# STM32L452xx register map
File version: 1.0
Registers are 32-bit, read-write, reset 0x0 unless marked. A register's access mark holds for its fields unless they carry their own. Offsets are from the block's base; [hi:lo] are bit positions; lines under a group give offsets from that group; {n}, {i} and the like mark numbered series.

## CRC — CRC calculation unit
Base 0x40023000
0x00 DR — CRC Data register
  [31:0] DR — Data register bits
0x04 IDR 8-bit — CRC Independent data register
  [7:0] IDR — General-purpose 8-bit data register bits
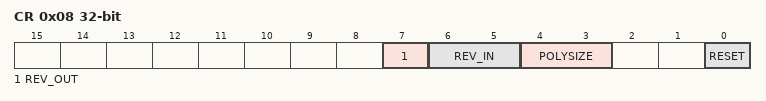
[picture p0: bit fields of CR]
0x08 CR — CRC Control register
  [7] REV_OUT — REV_OUT Reverse Output Data bits
    0=NONE (Output Data bit order not affected); 1=BIT (Output Data bit reversal done by bit)
  [6:5] REV_IN — REV_IN Reverse Input Data bits
    0=NONE (Input Data bit order not affected); 1=BYTE (Input Data bit reversal done by byte); 2=HALFWORD (Input Data bit reversal done by half-word); 3=WORD (Input Data bit reversal done by word)
  [4:3] POLYSIZE — Polynomial size bits
    0=POLYLENGTH_32B (32 bits Polynomial size); 1=POLYLENGTH_16B (16 bits Polynomial size); 2=POLYLENGTH_8B (8 bits Polynomial size); 3=POLYLENGTH_7B (7 bits Polynomial size)
  [0] RESET — RESET the CRC computation unit bit
0x10 INIT — Initial CRC value register
  [31:0] INIT — Initial CRC value bits
0x14 POL — CRC polynomial register
  [31:0] POL — Coefficients of the polynomial

## TSC — Touch Sensing Controller (TSC)
Base 0x40024000
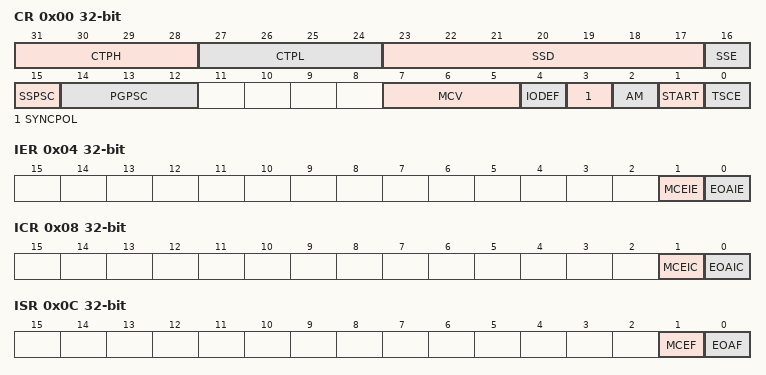
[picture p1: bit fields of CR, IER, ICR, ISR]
0x00 CR — TSC control register
  [31:28] CTPH — CTPH[3:0] bits (Charge Transfer pulse high)
  [27:24] CTPL — CTPL[3:0] bits (Charge Transfer pulse low)
  [23:17] SSD — SSD[6:0] bits (Spread Spectrum Deviation)
  [16] SSE — Spread Spectrum Enable
  [15] SSPSC — Spread Spectrum Prescaler
  [14:12] PGPSC — PGPSC[2:0] bits (Pulse Generator Prescaler)
  [7:5] MCV — MCV[2:0] bits (Max Count Value)
  [4] IODEF — IO default mode
  [3] SYNCPOL — Synchronization pin polarity
  [2] AM — Acquisition mode
  [1] START — Start acquisition
  [0] TSCE — Touch sensing controller enable
0x04 IER — TSC interrupt enable register
  [1] MCEIE — Max count error interrupt enable
  [0] EOAIE — End of acquisition interrupt enable
0x08 ICR — TSC interrupt clear register
  [1] MCEIC — Max count error interrupt clear
  [0] EOAIC — End of acquisition interrupt clear
0x0C ISR — TSC interrupt status register
  [1] MCEF — Max count error flag
  [0] EOAF — End of acquisition flag
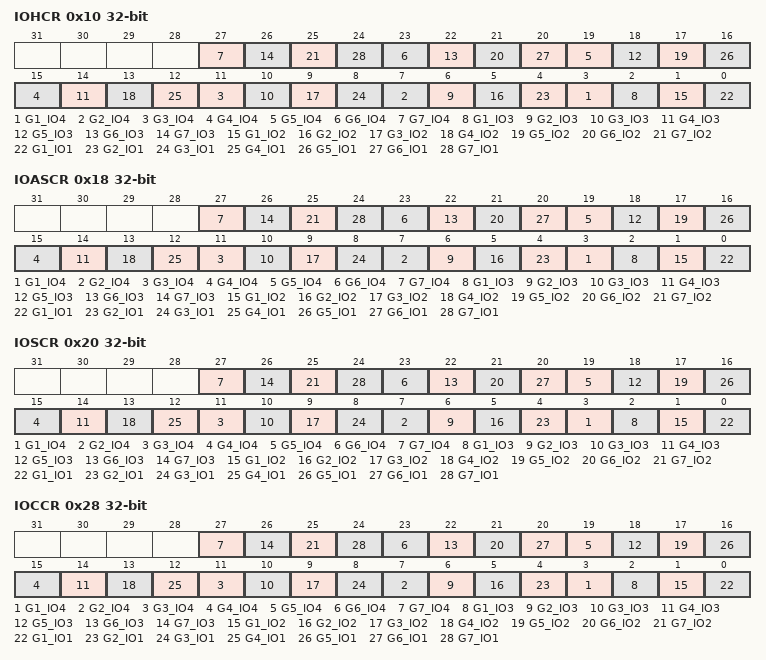
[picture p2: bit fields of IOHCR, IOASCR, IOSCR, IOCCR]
0x10 IOHCR — TSC I/O hysteresis control register
  [4n-1] G{n}_IO4 (n=1..7) — GROUP{n}_IO4 schmitt trigger hysteresis mode
  [4n-2] G{n}_IO3 (n=1..7) — GROUP{n}_IO3 schmitt trigger hysteresis mode
  [4n-3] G{n}_IO2 (n=1..7) — GROUP{n}_IO2 schmitt trigger hysteresis mode
  [4n-4] G{n}_IO1 (n=1..7) — GROUP{n}_IO1 schmitt trigger hysteresis mode
0x18 IOASCR — TSC I/O analog switch control register
  [4n-1] G{n}_IO4 (n=1..7) — GROUP{n}_IO4 analog switch enable
  [4n-2] G{n}_IO3 (n=1..7) — GROUP{n}_IO3 analog switch enable
  [4n-3] G{n}_IO2 (n=1..7) — GROUP{n}_IO2 analog switch enable
  [4n-4] G{n}_IO1 (n=1..7) — GROUP{n}_IO1 analog switch enable
0x20 IOSCR — TSC I/O sampling control register
  [4n-1] G{n}_IO4 (n=1..7) — GROUP{n}_IO4 sampling mode
  [4n-2] G{n}_IO3 (n=1..7) — GROUP{n}_IO3 sampling mode
  [4n-3] G{n}_IO2 (n=1..7) — GROUP{n}_IO2 sampling mode
  [4n-4] G{n}_IO1 (n=1..7) — GROUP{n}_IO1 sampling mode
0x28 IOCCR — TSC I/O channel control register
  [4n-1] G{n}_IO4 (n=1..7) — GROUP{n}_IO4 channel mode
  [4n-2] G{n}_IO3 (n=1..7) — GROUP{n}_IO3 channel mode
  [4n-3] G{n}_IO2 (n=1..7) — GROUP{n}_IO2 channel mode
  [4n-4] G{n}_IO1 (n=1..7) — GROUP{n}_IO1 channel mode
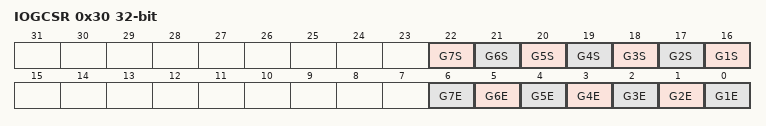
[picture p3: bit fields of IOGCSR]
0x30 IOGCSR — TSC I/O group control status register
  [n+15] G{n}S (n=1..7) — Analog IO GROUP{n} status
  [n-1] G{n}E (n=1..7) — Analog IO GROUP{n} enable
{0x30+4i} IOG{i}CR (i=1..7) — TSC I/O group x counter register
  [13:0] CNT — CNT[13:0] bits (Counter value)

## GPIOA — General Purpose I/O
Base 0x48000000
Same registers: GPIOB 0x48000400, GPIOC 0x48000800, GPIOD 0x48000C00, GPIOE 0x48001000, GPIOH 0x48001C00
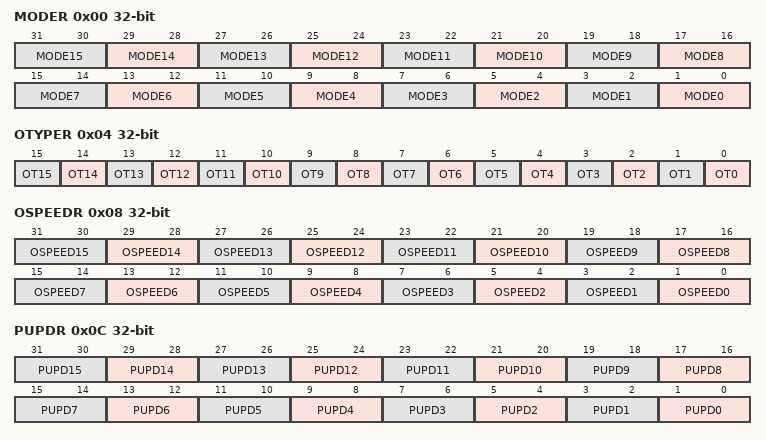
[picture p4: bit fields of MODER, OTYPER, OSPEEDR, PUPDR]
0x00 MODER — GPIO port mode register
  [2n+1:2n] MODE{n} (n=0..15)
0x04 OTYPER — GPIO port output type register
  [n] OT{n} (n=0..15)
0x08 OSPEEDR — GPIO port output speed register
  [2n+1:2n] OSPEED{n} (n=0..15)
0x0C PUPDR — GPIO port pull-up/pull-down register
  [2n+1:2n] PUPD{n} (n=0..15)
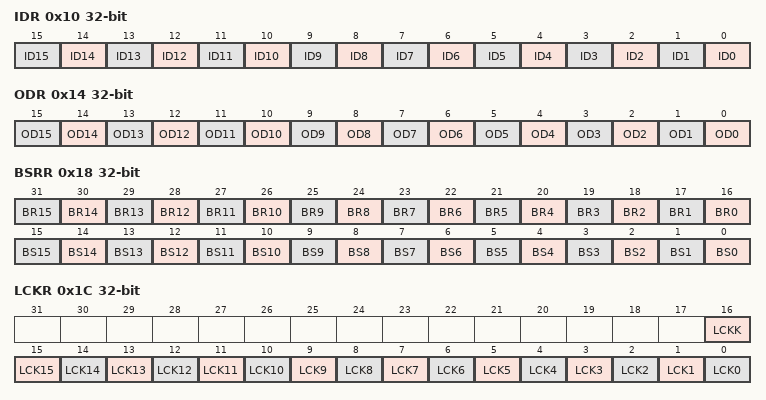
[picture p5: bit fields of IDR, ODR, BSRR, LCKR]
0x10 IDR — GPIO port input data register
  [n] ID{n} (n=0..15)
0x14 ODR — GPIO port output data register
  [n] OD{n} (n=0..15)
0x18 BSRR — GPIO port bit set/reset register
  [n+16] BR{n} (n=0..15), [n] BS{n} (n=0..15)
0x1C LCKR — GPIO port configuration lock register
  [16] LCKK, [n] LCK{n} (n=0..15)
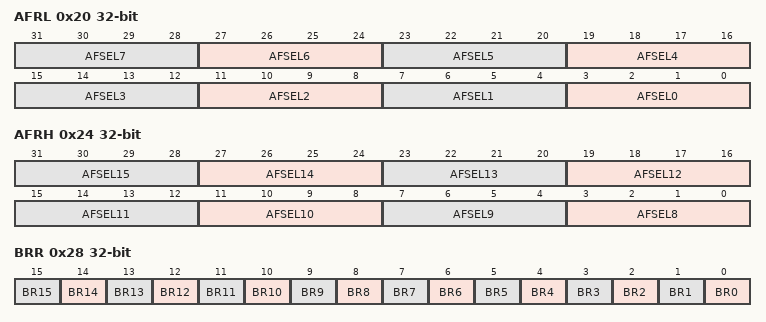
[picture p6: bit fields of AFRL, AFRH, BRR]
0x20 AFRL — GPIO alternate function registers
  [4n+3:4n] AFSEL{n} (n=0..7)
0x24 AFRH — GPIO alternate function registers
  [4n-29:4n-32] AFSEL{n} (n=8..15)
0x28 BRR — GPIO Bit Reset register
  [n] BR{n} (n=0..15)

## RNG
Base 0x50060800
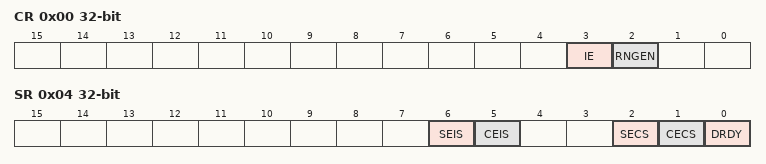
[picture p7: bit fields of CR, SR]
0x00 CR — RNG control register
  [3] IE, [2] RNGEN
0x04 SR — RNG status register
  [6] SEIS, [5] CEIS, [2] SECS, [1] CECS, [0] DRDY
0x08 DR — RNG data register

## QUADSPI — QUAD Serial Peripheral Interface
Base 0xA0001000
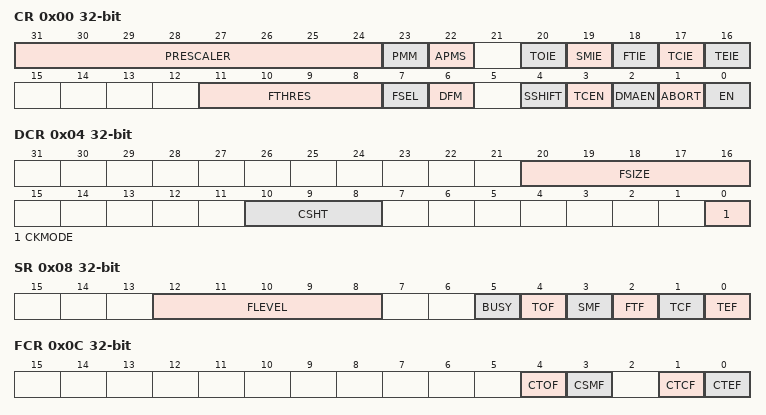
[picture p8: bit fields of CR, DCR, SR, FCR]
0x00 CR — QUADSPI Control register
  [31:24] PRESCALER — PRESCALER[7:0] Clock prescaler
  [23] PMM — Polling Match Mode
  [22] APMS — Automatic Polling Mode Stop
  [20] TOIE — TimeOut Interrupt Enable
  [19] SMIE — Status Match Interrupt Enable
  [18] FTIE — FIFO Threshold Interrupt Enable
  [17] TCIE — Transfer Complete Interrupt Enable
  [16] TEIE — Transfer Error Interrupt Enable
  [11:8] FTHRES — FTHRES[3:0] FIFO Level
  [7] FSEL — Flash memory selection
  [6] DFM — Dual-flash mode
  [4] SSHIFT — Sample Shift
  [3] TCEN — Timeout Counter Enable
  [2] DMAEN — DMA Enable
  [1] ABORT — Abort request
  [0] EN — Enable
0x04 DCR — QUADSPI Device Configuration register
  [20:16] FSIZE — FSIZE[4:0]: Flash Size
  [10:8] CSHT — CSHT[2:0]: ChipSelect High Time
  [0] CKMODE — Mode 0 / Mode 3
0x08 SR — QUADSPI Status register
  [12:8] FLEVEL — FIFO Threshlod Flag
  [5] BUSY
  [4] TOF — Timeout Flag
  [3] SMF — Status Match Flag
  [2] FTF — FIFO Threshlod Flag
  [1] TCF — Transfer Complete Flag
  [0] TEF — Transfer Error Flag
0x0C FCR — QUADSPI Flag Clear register
  [4] CTOF — Clear Timeout Flag
  [3] CSMF — Clear Status Match Flag
  [1] CTCF — Clear Transfer Complete Flag
  [0] CTEF — Clear Transfer Error Flag
0x10 DLR — QUADSPI Data Length register
  [31:0] DL — DL[31:0]: Data Length
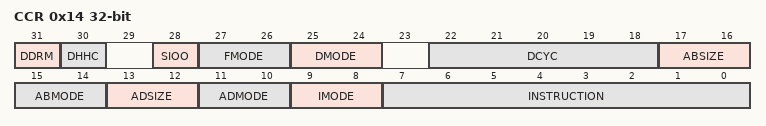
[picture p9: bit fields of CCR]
0x14 CCR — QUADSPI Communication Configuration register
  [31] DDRM — DDRM: Double Data Rate Mode
  [30] DHHC — DHHC: DDR hold
  [28] SIOO — SIOO: Send Instruction Only Once Mode
  [27:26] FMODE — FMODE[1:0]: Functional Mode
  [25:24] DMODE — DMODE[1:0]: Data Mode
  [22:18] DCYC — DCYC[4:0]: Dummy Cycles
  [17:16] ABSIZE — ABSIZE[1:0]: Instruction Mode
  [15:14] ABMODE — ABMODE[1:0]: Alternate Bytes Mode
  [13:12] ADSIZE — ADSIZE[1:0]: Address Size
  [11:10] ADMODE — ADMODE[1:0]: Address Mode
  [9:8] IMODE — IMODE[1:0]: Instruction Mode
  [7:0] INSTRUCTION — INSTRUCTION[7:0]: Instruction
0x18 AR — QUADSPI Address register
  [31:0] ADDRESS — ADDRESS[31:0]: Address
0x1C ABR — QUADSPI Alternate Bytes register
  [31:0] ALTERNATE — ALTERNATE[31:0]: Alternate Bytes
0x20 DR — QUADSPI Data register
  [31:0] DATA — DATA[31:0]: Data
0x24 PSMKR — QUADSPI Polling Status Mask register
  [31:0] MASK — MASK[31:0]: Status Mask
0x28 PSMAR — QUADSPI Polling Status Match register
  [31:0] MATCH — MATCH[31:0]: Status Match
0x2C PIR — QUADSPI Polling Interval register
  [15:0] INTERVAL — INTERVAL[15:0]: Polling Interval
0x30 LPTR — QUADSPI Low Power Timeout register
  [15:0] TIMEOUT — TIMEOUT[15:0]: Timeout period

## DBGMCU — Debug MCU
Base 0xE0042000
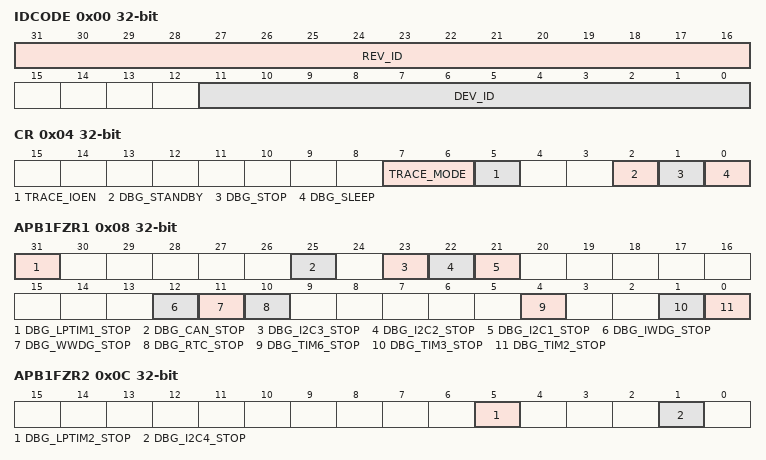
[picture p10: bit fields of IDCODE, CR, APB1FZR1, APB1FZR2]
0x00 IDCODE — MCU device ID code
  [31:16] REV_ID, [11:0] DEV_ID
0x04 CR — Debug MCU configuration register
  [7:6] TRACE_MODE, [5] TRACE_IOEN, [2] DBG_STANDBY, [1] DBG_STOP, [0] DBG_SLEEP
0x08 APB1FZR1 — Debug MCU APB1 freeze register 1
  [31] DBG_LPTIM1_STOP, [25] DBG_CAN_STOP, [23] DBG_I2C3_STOP, [22] DBG_I2C2_STOP, [21] DBG_I2C1_STOP, [12] DBG_IWDG_STOP, [11] DBG_WWDG_STOP, [10] DBG_RTC_STOP, [4] DBG_TIM6_STOP, [1] DBG_TIM3_STOP, [0] DBG_TIM2_STOP
0x0C APB1FZR2 — Debug MCU APB1 freeze register 2
  [5] DBG_LPTIM2_STOP, [1] DBG_I2C4_STOP
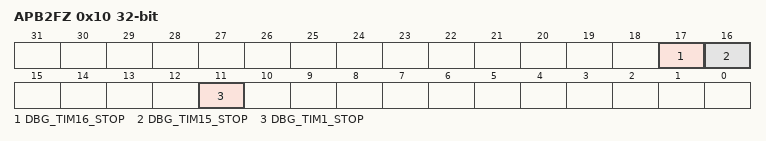
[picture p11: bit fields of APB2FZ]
0x10 APB2FZ — Debug MCU APB2 freeze register
  [17] DBG_TIM16_STOP, [16] DBG_TIM15_STOP, [11] DBG_TIM1_STOP
